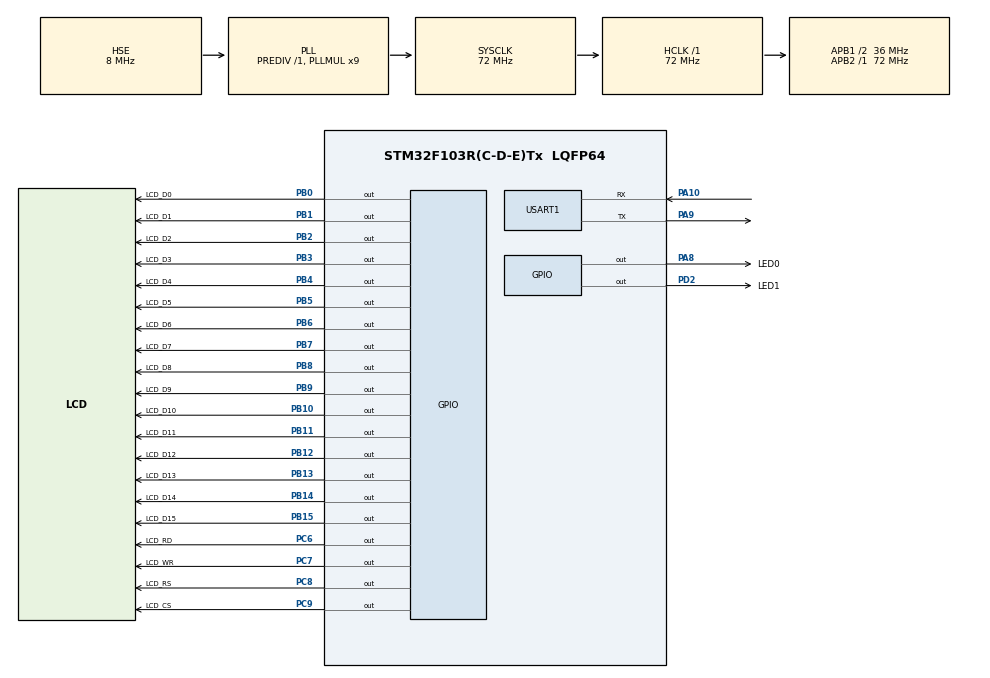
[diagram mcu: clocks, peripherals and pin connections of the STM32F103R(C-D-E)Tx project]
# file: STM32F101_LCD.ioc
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Mcu.Family=STM32F1
Mcu.Name=STM32F103R(C-D-E)Tx
Mcu.Package=LQFP64
NVIC.PriorityGroup=NVIC_PRIORITYGROUP_4
NVIC.USART1_IRQn=true\:0\:0\:false\:false\:true\:true\:true\:true
PA10.Mode=Asynchronous
PA10.Signal=USART1_RX
PA13.Mode=Serial_Wire
PA13.Signal=SYS_JTMS-SWDIO
PA14.Mode=Serial_Wire
PA14.Signal=SYS_JTCK-SWCLK
PA8.GPIO_Label=LED0
PA8.Signal=GPIO_Output
PA9.Mode=Asynchronous
PA9.Signal=USART1_TX
PB0.GPIO_Label=LCD_D0
PB0.GPIO_PuPd=GPIO_PULLUP
PB0.GPIO_Speed=GPIO_SPEED_FREQ_HIGH
PB0.PinState=GPIO_PIN_SET
PB0.Signal=GPIO_Output
PB1.GPIO_Label=LCD_D1
PB1.GPIO_PuPd=GPIO_PULLUP
PB1.GPIO_Speed=GPIO_SPEED_FREQ_HIGH
PB1.PinState=GPIO_PIN_SET
PB1.Signal=GPIO_Output
PB10.GPIO_Label=LCD_D10
PB10.GPIO_PuPd=GPIO_PULLUP
PB10.GPIO_Speed=GPIO_SPEED_FREQ_HIGH
PB10.PinState=GPIO_PIN_SET
PB10.Signal=GPIO_Output
PB11.GPIO_Label=LCD_D11
PB11.GPIO_PuPd=GPIO_PULLUP
PB11.GPIO_Speed=GPIO_SPEED_FREQ_HIGH
PB11.PinState=GPIO_PIN_SET
PB11.Signal=GPIO_Output
PB12.GPIO_Label=LCD_D12
PB12.GPIO_PuPd=GPIO_PULLUP
PB12.GPIO_Speed=GPIO_SPEED_FREQ_HIGH
PB12.PinState=GPIO_PIN_SET
PB12.Signal=GPIO_Output
PB13.GPIO_Label=LCD_D13
PB13.GPIO_PuPd=GPIO_PULLUP
PB13.GPIO_Speed=GPIO_SPEED_FREQ_HIGH
PB13.PinState=GPIO_PIN_SET
PB13.Signal=GPIO_Output
PB14.GPIO_Label=LCD_D14
PB14.GPIO_PuPd=GPIO_PULLUP
PB14.GPIO_Speed=GPIO_SPEED_FREQ_HIGH
PB14.PinState=GPIO_PIN_SET
PB14.Signal=GPIO_Output
PB15.GPIO_Label=LCD_D15
PB15.GPIO_PuPd=GPIO_PULLUP
PB15.GPIO_Speed=GPIO_SPEED_FREQ_HIGH
PB15.PinState=GPIO_PIN_SET
PB15.Signal=GPIO_Output
PB2.GPIO_Label=LCD_D2
PB2.GPIO_PuPd=GPIO_PULLUP
PB2.GPIO_Speed=GPIO_SPEED_FREQ_HIGH
PB2.PinState=GPIO_PIN_SET
PB2.Signal=GPIO_Output
PB3.GPIO_Label=LCD_D3
PB3.GPIO_PuPd=GPIO_PULLUP
PB3.GPIO_Speed=GPIO_SPEED_FREQ_HIGH
PB3.PinState=GPIO_PIN_SET
PB3.Signal=GPIO_Output
PB4.GPIO_Label=LCD_D4
PB4.GPIO_PuPd=GPIO_PULLUP
PB4.GPIO_Speed=GPIO_SPEED_FREQ_HIGH
PB4.PinState=GPIO_PIN_SET
PB4.Signal=GPIO_Output
PB5.GPIO_Label=LCD_D5
PB5.GPIO_PuPd=GPIO_PULLUP
PB5.GPIO_Speed=GPIO_SPEED_FREQ_HIGH
PB5.PinState=GPIO_PIN_SET
PB5.Signal=GPIO_Output
PB6.GPIO_Label=LCD_D6
PB6.GPIO_PuPd=GPIO_PULLUP
PB6.GPIO_Speed=GPIO_SPEED_FREQ_HIGH
PB6.PinState=GPIO_PIN_SET
PB6.Signal=GPIO_Output
PB7.GPIO_Label=LCD_D7
PB7.GPIO_PuPd=GPIO_PULLUP
PB7.GPIO_Speed=GPIO_SPEED_FREQ_HIGH
PB7.PinState=GPIO_PIN_SET
PB7.Signal=GPIO_Output
PB8.GPIO_Label=LCD_D8
PB8.GPIO_PuPd=GPIO_PULLUP
PB8.GPIO_Speed=GPIO_SPEED_FREQ_HIGH
PB8.PinState=GPIO_PIN_SET
PB8.Signal=GPIO_Output
PB9.GPIO_Label=LCD_D9
PB9.GPIO_PuPd=GPIO_PULLUP
PB9.GPIO_Speed=GPIO_SPEED_FREQ_HIGH
PB9.PinState=GPIO_PIN_SET
PB9.Signal=GPIO_Output
PC6.GPIO_Label=LCD_RD
PC6.GPIO_PuPd=GPIO_PULLUP
PC6.GPIO_Speed=GPIO_SPEED_FREQ_HIGH
PC6.PinState=GPIO_PIN_SET
PC6.Signal=GPIO_Output
PC7.GPIO_Label=LCD_WR
PC7.GPIO_PuPd=GPIO_PULLUP
PC7.GPIO_Speed=GPIO_SPEED_FREQ_HIGH
PC7.PinState=GPIO_PIN_SET
PC7.Signal=GPIO_Output
PC8.GPIO_Label=LCD_RS
PC8.GPIO_PuPd=GPIO_PULLUP
PC8.GPIO_Speed=GPIO_SPEED_FREQ_HIGH
PC8.PinState=GPIO_PIN_SET
PC8.Signal=GPIO_Output
PC9.GPIO_Label=LCD_CS
PC9.GPIO_PuPd=GPIO_PULLUP
PC9.GPIO_Speed=GPIO_SPEED_FREQ_HIGH
PC9.PinState=GPIO_PIN_SET
PC9.Signal=GPIO_Output
PD0-OSC_IN.Mode=HSE-External-Oscillator
PD0-OSC_IN.Signal=RCC_OSC_IN
PD1-OSC_OUT.Mode=HSE-External-Oscillator
PD1-OSC_OUT.Signal=RCC_OSC_OUT
PD2.GPIO_Label=LED1
PD2.Signal=GPIO_Output
ProjectManager.HeapSize=0x200
ProjectManager.StackSize=0x400
ProjectManager.TargetToolchain=STM32CubeIDE
RCC.AHBFreq_Value=72000000
RCC.APB1CLKDivider=RCC_HCLK_DIV2
RCC.APB1Freq_Value=36000000
RCC.APB1TimFreq_Value=72000000
RCC.APB2Freq_Value=72000000
RCC.APB2TimFreq_Value=72000000
RCC.HCLKFreq_Value=72000000
RCC.PLLMUL=RCC_PLL_MUL9
RCC.PLLSourceVirtual=RCC_PLLSOURCE_HSE
RCC.SYSCLKFreq_VALUE=72000000
RCC.SYSCLKSource=RCC_SYSCLKSOURCE_PLLCLK
RCC.USBFreq_Value=72000000
USART1.VirtualMode=VM_ASYNC
board=custom

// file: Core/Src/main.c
/* USER CODE BEGIN Header */
/**
  ******************************************************************************
  * @file           : main.c
  * @brief          : Main program body
  ******************************************************************************
  * @attention
  *
  * Copyright (c) 2022 STMicroelectronics.
  * All rights reserved.
  *
  * This software is licensed under terms that can be found in the LICENSE file
  * in the root directory of this software component.
  * If no LICENSE file comes with this software, it is provided AS-IS.
  *
  ******************************************************************************
  */
/* USER CODE END Header */
#include "main.h"

/* USER CODE BEGIN Includes */
#include "UserMain.h"
/* USER CODE END Includes */

UART_HandleTypeDef huart1;

void SystemClock_Config(void);
static void MX_GPIO_Init(void);
static void MX_USART1_UART_Init(void);

int main(void)
{

  /* MCU Configuration--------------------------------------------------------*/

  /* Reset of all peripherals, Initializes the Flash interface and the Systick. */
  HAL_Init();

  /* Configure the system clock */
  SystemClock_Config();

  /* Initialize all configured peripherals */
  MX_GPIO_Init();
  MX_USART1_UART_Init();
  /* USER CODE BEGIN 2 */
    UserSysInit();
    UserConfigInit();
  /* USER CODE END 2 */

  /* Infinite loop */
  /* USER CODE BEGIN WHILE */
    while (1) {
        UserLoop();
    /* USER CODE END WHILE */

    }
}

void SystemClock_Config(void)
{
  RCC_OscInitTypeDef RCC_OscInitStruct = {0};
  RCC_ClkInitTypeDef RCC_ClkInitStruct = {0};

  /** Initializes the RCC Oscillators according to the specified parameters
  * in the RCC_OscInitTypeDef structure.
  */
  RCC_OscInitStruct.OscillatorType = RCC_OSCILLATORTYPE_HSE;
  RCC_OscInitStruct.HSEState = RCC_HSE_ON;
  RCC_OscInitStruct.HSEPredivValue = RCC_HSE_PREDIV_DIV1;
  RCC_OscInitStruct.HSIState = RCC_HSI_ON;
  RCC_OscInitStruct.PLL.PLLState = RCC_PLL_ON;
  RCC_OscInitStruct.PLL.PLLSource = RCC_PLLSOURCE_HSE;
  RCC_OscInitStruct.PLL.PLLMUL = RCC_PLL_MUL9;
  if (HAL_RCC_OscConfig(&RCC_OscInitStruct) != HAL_OK)
  {
    Error_Handler();
  }

  /** Initializes the CPU, AHB and APB buses clocks
  */
  RCC_ClkInitStruct.ClockType = RCC_CLOCKTYPE_HCLK|RCC_CLOCKTYPE_SYSCLK
                              |RCC_CLOCKTYPE_PCLK1|RCC_CLOCKTYPE_PCLK2;
  RCC_ClkInitStruct.SYSCLKSource = RCC_SYSCLKSOURCE_PLLCLK;
  RCC_ClkInitStruct.AHBCLKDivider = RCC_SYSCLK_DIV1;
  RCC_ClkInitStruct.APB1CLKDivider = RCC_HCLK_DIV2;
  RCC_ClkInitStruct.APB2CLKDivider = RCC_HCLK_DIV1;

  if (HAL_RCC_ClockConfig(&RCC_ClkInitStruct, FLASH_LATENCY_2) != HAL_OK)
  {
    Error_Handler();
  }
}

static void MX_USART1_UART_Init(void)
{

  huart1.Instance = USART1;
  huart1.Init.BaudRate = 115200;
  huart1.Init.WordLength = UART_WORDLENGTH_8B;
  huart1.Init.StopBits = UART_STOPBITS_1;
  huart1.Init.Parity = UART_PARITY_NONE;
  huart1.Init.Mode = UART_MODE_TX_RX;
  huart1.Init.HwFlowCtl = UART_HWCONTROL_NONE;
  huart1.Init.OverSampling = UART_OVERSAMPLING_16;
  if (HAL_UART_Init(&huart1) != HAL_OK)
  {
    Error_Handler();
  }

}

static void MX_GPIO_Init(void)
{
  GPIO_InitTypeDef GPIO_InitStruct = {0};

  /* GPIO Ports Clock Enable */
  __HAL_RCC_GPIOD_CLK_ENABLE();
  __HAL_RCC_GPIOB_CLK_ENABLE();
  __HAL_RCC_GPIOC_CLK_ENABLE();
  __HAL_RCC_GPIOA_CLK_ENABLE();

  /*Configure GPIO pin Output Level */
  HAL_GPIO_WritePin(GPIOB, LCD_D0_Pin|LCD_D1_Pin|LCD_D2_Pin|LCD_D10_Pin
                          |LCD_D11_Pin|LCD_D12_Pin|LCD_D13_Pin|LCD_D14_Pin
                          |LCD_D15_Pin|LCD_D3_Pin|LCD_D4_Pin|LCD_D5_Pin
                          |LCD_D6_Pin|LCD_D7_Pin|LCD_D8_Pin|LCD_D9_Pin, GPIO_PIN_SET);

  /*Configure GPIO pin Output Level */
  HAL_GPIO_WritePin(GPIOC, LCD_RD_Pin|LCD_WR_Pin|LCD_RS_Pin|LCD_CS_Pin, GPIO_PIN_SET);

  /*Configure GPIO pin Output Level */
  HAL_GPIO_WritePin(LED0_GPIO_Port, LED0_Pin, GPIO_PIN_RESET);

  /*Configure GPIO pin Output Level */
  HAL_GPIO_WritePin(LED1_GPIO_Port, LED1_Pin, GPIO_PIN_RESET);

  /*Configure GPIO pins : LCD_D0_Pin LCD_D1_Pin LCD_D2_Pin LCD_D10_Pin
                           LCD_D11_Pin LCD_D12_Pin LCD_D13_Pin LCD_D14_Pin
                           LCD_D15_Pin LCD_D3_Pin LCD_D4_Pin LCD_D5_Pin
                           LCD_D6_Pin LCD_D7_Pin LCD_D8_Pin LCD_D9_Pin */
  GPIO_InitStruct.Pin = LCD_D0_Pin|LCD_D1_Pin|LCD_D2_Pin|LCD_D10_Pin
                          |LCD_D11_Pin|LCD_D12_Pin|LCD_D13_Pin|LCD_D14_Pin
                          |LCD_D15_Pin|LCD_D3_Pin|LCD_D4_Pin|LCD_D5_Pin
                          |LCD_D6_Pin|LCD_D7_Pin|LCD_D8_Pin|LCD_D9_Pin;
  GPIO_InitStruct.Mode = GPIO_MODE_OUTPUT_PP;
  GPIO_InitStruct.Pull = GPIO_PULLUP;
  GPIO_InitStruct.Speed = GPIO_SPEED_FREQ_HIGH;
  HAL_GPIO_Init(GPIOB, &GPIO_InitStruct);

  /*Configure GPIO pins : LCD_RD_Pin LCD_WR_Pin LCD_RS_Pin LCD_CS_Pin */
  GPIO_InitStruct.Pin = LCD_RD_Pin|LCD_WR_Pin|LCD_RS_Pin|LCD_CS_Pin;
  GPIO_InitStruct.Mode = GPIO_MODE_OUTPUT_PP;
  GPIO_InitStruct.Pull = GPIO_PULLUP;
  GPIO_InitStruct.Speed = GPIO_SPEED_FREQ_HIGH;
  HAL_GPIO_Init(GPIOC, &GPIO_InitStruct);

  /*Configure GPIO pin : LED0_Pin */
  GPIO_InitStruct.Pin = LED0_Pin;
  GPIO_InitStruct.Mode = GPIO_MODE_OUTPUT_PP;
  GPIO_InitStruct.Pull = GPIO_NOPULL;
  GPIO_InitStruct.Speed = GPIO_SPEED_FREQ_LOW;
  HAL_GPIO_Init(LED0_GPIO_Port, &GPIO_InitStruct);

  /*Configure GPIO pin : LED1_Pin */
  GPIO_InitStruct.Pin = LED1_Pin;
  GPIO_InitStruct.Mode = GPIO_MODE_OUTPUT_PP;
  GPIO_InitStruct.Pull = GPIO_NOPULL;
  GPIO_InitStruct.Speed = GPIO_SPEED_FREQ_LOW;
  HAL_GPIO_Init(LED1_GPIO_Port, &GPIO_InitStruct);

}

void Error_Handler(void)
{
    __disable_irq();
    while (1) {
    }
}
